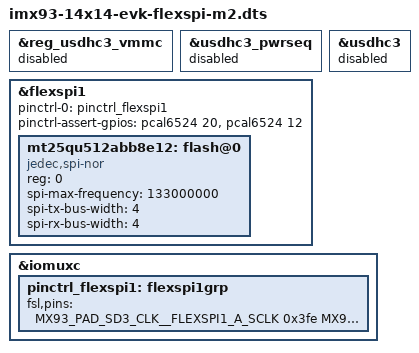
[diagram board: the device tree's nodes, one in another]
// SPDX-License-Identifier: (GPL-2.0+ OR MIT)
/*
 * Copyright 2023 NXP
 */

#include "imx93-14x14-evk.dts"

&reg_usdhc3_vmmc {
	status = "disabled";
};

&usdhc3_pwrseq {
	status = "disabled";
};

&usdhc3 {
	status = "disabled";
};

&flexspi1 {
	pinctrl-names = "default";
	pinctrl-0 = <&pinctrl_flexspi1>;
	pinctrl-assert-gpios = <&pcal6524 20 GPIO_ACTIVE_HIGH>,  /* enable SPI-NOR VCC 1.8v */
			       <&pcal6524 12 GPIO_ACTIVE_HIGH>;  /* put SPI-NOR RST pin to 1.8v */
	status = "okay";

	mt25qu512abb8e12: flash@0 {
		reg = <0>;
		#address-cells = <1>;
		#size-cells = <1>;
		compatible = "jedec,spi-nor";
		spi-max-frequency = <133000000>;
		spi-tx-bus-width = <4>;
		spi-rx-bus-width = <4>;
	};
};

&iomuxc {
	pinctrl_flexspi1: flexspi1grp {
		fsl,pins = <
			MX93_PAD_SD3_CLK__FLEXSPI1_A_SCLK	0x3fe
			MX93_PAD_SD3_CMD__FLEXSPI1_A_SS0_B	0x3fe
			MX93_PAD_SD3_DATA0__FLEXSPI1_A_DATA00	0x3fe
			MX93_PAD_SD3_DATA1__FLEXSPI1_A_DATA01	0x3fe
			MX93_PAD_SD3_DATA2__FLEXSPI1_A_DATA02	0x3fe
			MX93_PAD_SD3_DATA3__FLEXSPI1_A_DATA03	0x3fe
		>;
	};
};
